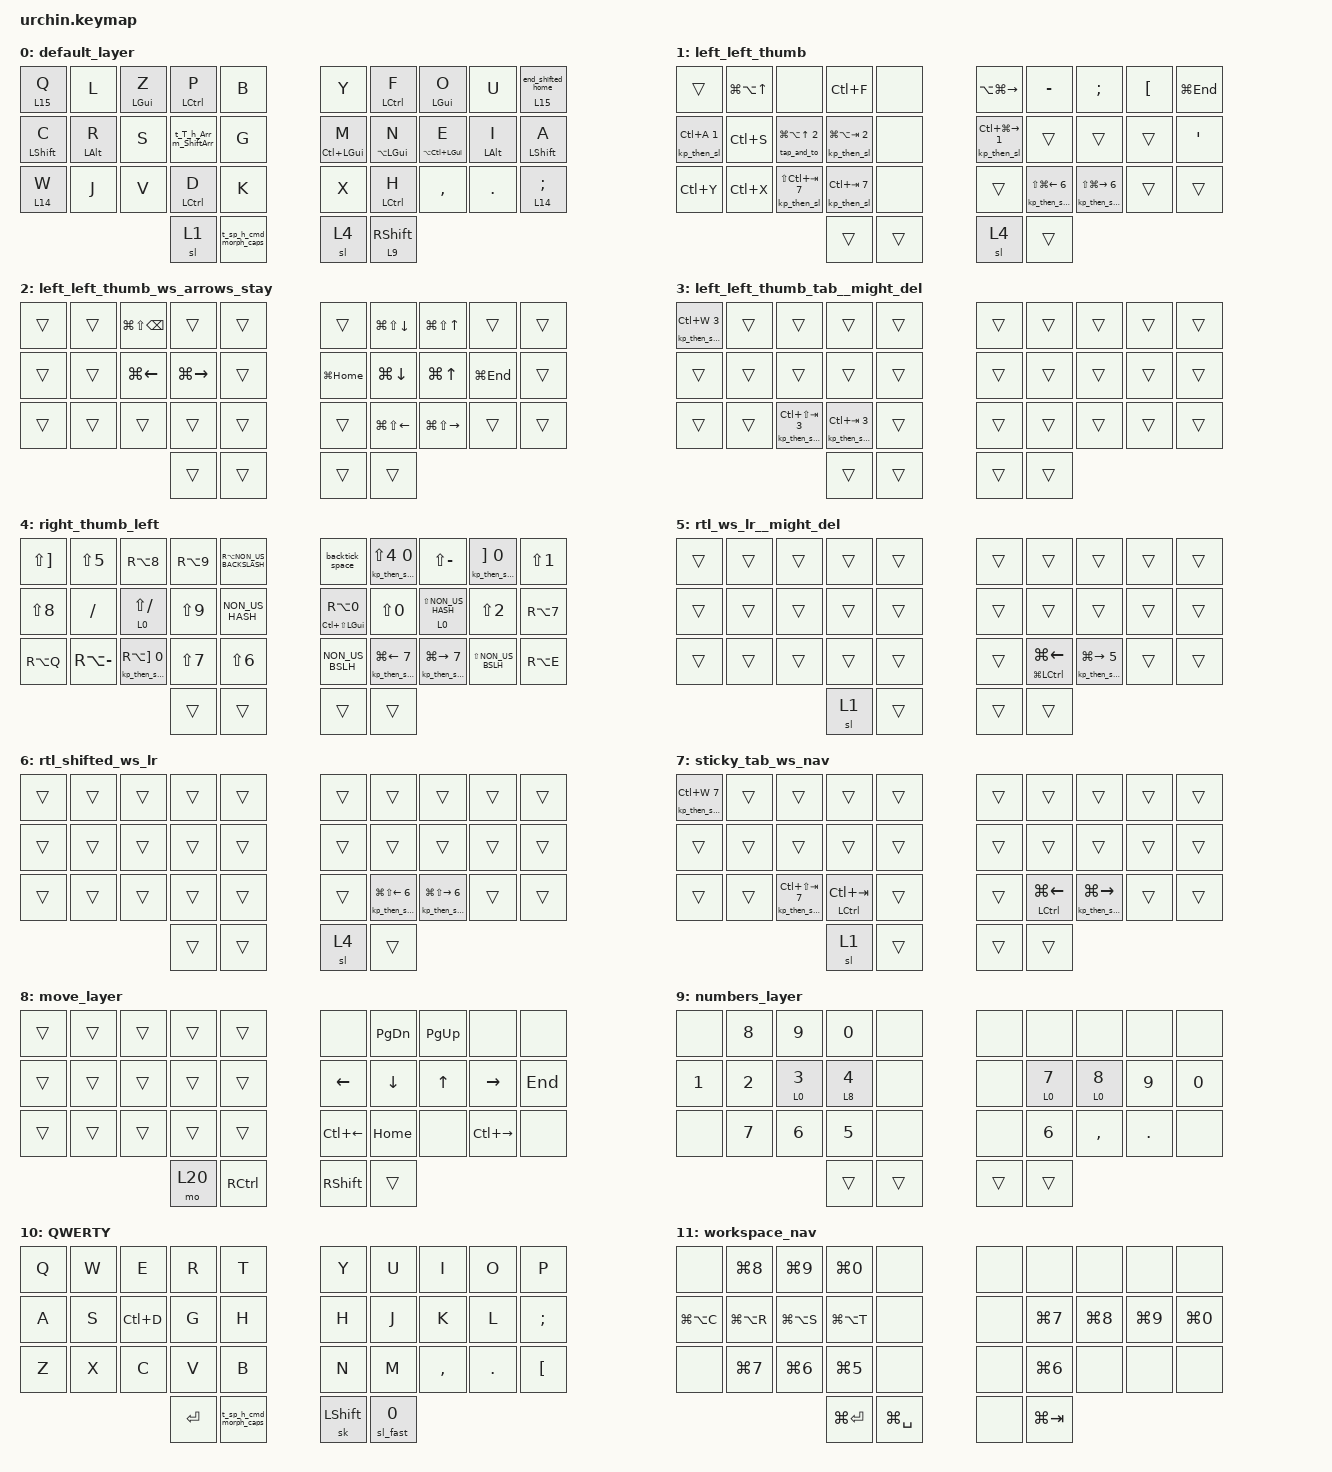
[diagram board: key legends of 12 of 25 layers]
// Copyright (c) 2022 The ZMK Contributors
// SPDX-License-Identifier: MIT

#include <behaviors.dtsi>
#include <dt-bindings/zmk/bt.h>
#include <dt-bindings/zmk/keys.h>
#include <dt-bindings/zmk/pointing.h>

&sk {
    release-after-ms = <1500>;
    quick-release;
};

&lt { flavor = "balanced"; };

&caps_word { continue-list = <UNDERSCORE BACKSPACE DELETE SINGLE_QUOTE DOUBLE_QUOTES SEMICOLON LBRC LEFT_BRACE COLON QUESTION>; };

/ {
    behaviors {
        ht: hold_tap {
            compatible = "zmk,behavior-hold-tap";
            #binding-cells = <2>;
            flavor = "balanced";
            tapping-term-ms = <220>;
            quick-tap-ms = <150>;
            require-prior-idle-ms = <0>;
            bindings = <&kp>, <&kp>;
        };

        htl_undec: htl_undec {
            compatible = "zmk,behavior-hold-tap";
            label = "HTL_UNDEC";
            bindings = <&kp>, <&kp>;

            #binding-cells = <2>;
            tapping-term-ms = <350>;
            hold-trigger-key-positions = <5 6 7 8 9 15 16 17 18 19 25 26 27 28 29 32 33 30 31>;
            flavor = "balanced";
            quick-tap-ms = <175>;
            require-prior-idle-ms = <3>;
            hold-while-undecided;
            hold-trigger-on-release;
        };

        ltl: ltl {
            compatible = "zmk,behavior-hold-tap";
            label = "LTL";
            bindings = <&mo>, <&kp>;

            #binding-cells = <2>;
            tapping-term-ms = <350>;
            quick-tap-ms = <175>;
            require-prior-idle-ms = <3>;
            flavor = "balanced";
            hold-trigger-key-positions = <5 6 7 8 9 15 16 17 18 19 25 26 27 28 29 32 33 30 31>;
        };

        htr_undec: htr_undec {
            compatible = "zmk,behavior-hold-tap";
            label = "HTR_UNDEC";
            bindings = <&kp>, <&kp>;

            #binding-cells = <2>;
            flavor = "balanced";
            tapping-term-ms = <350>;
            hold-trigger-key-positions = <0 1 2 3 4 10 11 12 13 14 20 21 22 23 24 30 31 32 33>;
            require-prior-idle-ms = <3>;
            quick-tap-ms = <175>;
            hold-while-undecided;
            hold-trigger-on-release;
        };

        ltr: ltr {
            compatible = "zmk,behavior-hold-tap";
            label = "LTR";
            bindings = <&mo>, <&kp>;

            #binding-cells = <2>;
            tapping-term-ms = <350>;
            quick-tap-ms = <175>;
            require-prior-idle-ms = <3>;
            flavor = "balanced";
            hold-trigger-key-positions = <0 1 2 3 4 10 11 12 13 14 20 21 22 23 24 30 31 32 33>;
        };

        htr: htr {
            compatible = "zmk,behavior-hold-tap";
            label = "HTR";
            bindings = <&kp>, <&kp>;

            #binding-cells = <2>;
            flavor = "balanced";
            tapping-term-ms = <350>;
            hold-trigger-key-positions = <0 1 2 3 4 10 11 12 13 14 20 21 22 23 24 30 31 32 33>;
            require-prior-idle-ms = <3>;
            quick-tap-ms = <175>;
            hold-trigger-on-release;
            retro-tap;
        };

        htl: htl {
            compatible = "zmk,behavior-hold-tap";
            label = "HTL";
            bindings = <&kp>, <&kp>;

            #binding-cells = <2>;
            tapping-term-ms = <350>;
            hold-trigger-key-positions = <5 6 7 8 9 15 16 17 18 19 25 26 27 28 29 32 33 30 31>;
            flavor = "balanced";
            quick-tap-ms = <175>;
            require-prior-idle-ms = <3>;
            hold-trigger-on-release;
            retro-tap;
        };

        tsk_hmo: tsk_hmo {
            compatible = "zmk,behavior-hold-tap";
            label = "TSK_HMO";
            bindings = <&mo>, <&sk>;

            #binding-cells = <2>;
            tapping-term-ms = <200>;
            flavor = "balanced";
            retro-tap;
            require-prior-idle-ms = <0>;
        };

        slashBackslash: slashBackslash {
            compatible = "zmk,behavior-mod-morph";
            label = "SLASHBACKSLASH";
            bindings = <&kp LS(AMPERSAND)>, <&kp RA(MINUS)>;

            #binding-cells = <0>;
            mods = <(MOD_RSFT)>;
        };

        minusTilde: minusTilde {
            compatible = "zmk,behavior-mod-morph";
            label = "MINUSTILDE";
            bindings = <&kp SLASH>, <&kp RA(RIGHT_BRACKET)>;

            #binding-cells = <0>;
            mods = <(MOD_RSFT)>;
        };

        td_wsnav: td_wsnav {
            compatible = "zmk,behavior-tap-dance";
            label = "TD_WSNAV";
            #binding-cells = <0>;
            bindings = <&lt 17 TAB>, <&mo 11>;
        };

        sticky_number_shift_capsword: sticky_number_shift_capsword {
            compatible = "zmk,behavior-tap-dance";
            label = "STICKY_NUMBER_SHIFT_CAPSWORD";
            #binding-cells = <0>;
            bindings = <&tsk_hmo 9 RSHFT>, <&caps_word>;
        };

        lazy_sl: lazy_sl {
            compatible = "zmk,behavior-sticky-key";
            label = "LAZY_SL";
            bindings = <&mo>;
            #binding-cells = <1>;
            release-after-ms = <1000>;
            lazy;
            quick-release;
            ignore-modifiers;
        };

        htl_undec_idle_req: htl_undec_idle_req {
            compatible = "zmk,behavior-hold-tap";
            label = "HTL_UNDEC_IDLE_REQ";
            bindings = <&kp>, <&kp>;

            #binding-cells = <2>;
            hold-trigger-key-positions = <30 31 32 33 5 6 7 8 9 15 16 17 18 19 25 26 27 28 29>;
            hold-while-undecided;
            flavor = "balanced";
            tapping-term-ms = <350>;
            require-prior-idle-ms = <70>;
        };

        htr_undec_idle_req: htr_undec_idle_req {
            compatible = "zmk,behavior-hold-tap";
            label = "HTR_UNDEC_IDLE_REQ";
            bindings = <&kp>, <&kp>;

            #binding-cells = <2>;
            hold-while-undecided;
            flavor = "balanced";
            tapping-term-ms = <350>;
            require-prior-idle-ms = <70>;
            hold-trigger-key-positions = <0 1 2 3 4 10 11 12 13 14 20 21 22 23 24 30 31 32 33>;
        };

        ltr_idle_required: ltr_idle_required {
            compatible = "zmk,behavior-hold-tap";
            label = "LTR_IDLE_REQUIRED";
            bindings = <&mo>, <&kp>;

            #binding-cells = <2>;
            flavor = "balanced";
            require-prior-idle-ms = <50>;
            hold-trigger-key-positions = <0 1 2 3 4 10 11 12 13 14 20 21 22 23 24 30 31 32 33>;
            tapping-term-ms = <350>;
        };

        htl_idle_req: htl_idle_req {
            compatible = "zmk,behavior-hold-tap";
            label = "HTL_IDLE_REQ";
            bindings = <&kp>, <&kp>;

            #binding-cells = <2>;
            require-prior-idle-ms = <50>;
            tapping-term-ms = <350>;
            hold-trigger-key-positions = <30 31 32 33 5 6 7 8 9 15 16 17 18 19 25 26 27 28 29>;
            flavor = "balanced";
        };

        htr_idle_req: htr_idle_req {
            compatible = "zmk,behavior-hold-tap";
            label = "HTR_IDLE_REQ";
            bindings = <&kp>, <&kp>;

            #binding-cells = <2>;
            require-prior-idle-ms = <50>;
            tapping-term-ms = <350>;
            flavor = "balanced";
            hold-trigger-key-positions = <0 1 2 3 4 10 11 12 13 14 20 21 22 23 24 30 31 33 32>;
        };

        dot_capsword: dot_capsword {
            compatible = "zmk,behavior-mod-morph";
            label = "DOT_CAPSWORD";
            bindings = <&kp DOT>, <&caps_word>;

            #binding-cells = <0>;
            mods = <(MOD_RSFT)>;
        };

        sl_left_tab_morph: sl_left_tab_morph {
            compatible = "zmk,behavior-mod-morph";
            label = "SL_LEFT_TAB_MORPH";
            bindings = <&sl_fast 0>, <&kp TAB>;

            #binding-cells = <0>;
            mods = <(MOD_LCTL|MOD_LSFT|MOD_LGUI|MOD_RCTL|MOD_RSFT|MOD_RGUI)>;
            keep-mods = <(MOD_LCTL|MOD_LSFT|MOD_LGUI|MOD_RCTL|MOD_RSFT|MOD_RGUI)>;
        };

        tap_sl_hold_to: tap_sl_hold_to {
            compatible = "zmk,behavior-hold-tap";
            label = "TAP_SL_HOLD_TO";
            bindings = <&to>, <&sl_fast>;

            #binding-cells = <2>;
            flavor = "balanced";
            tapping-term-ms = <200>;
        };

        t_sp_h_cmd_morph_caps: t_sp_h_cmd_morph_caps {
            compatible = "zmk,behavior-mod-morph";
            label = "T_SP_H_CMD_MORPH_CAPS";
            bindings = <&lt 13 SPACE>, <&t_capsw_h_mo 13 0>;

            #binding-cells = <0>;
            mods = <(MOD_RSFT)>;
            keep-mods = <(MOD_RSFT)>;
        };

        t_capsw_h_mo: t_capsw_h_mo {
            compatible = "zmk,behavior-hold-tap";
            label = "T_CAPSW_H_MO";
            bindings = <&mo>, <&caps_word>;

            #binding-cells = <2>;
            tapping-term-ms = <200>;
            flavor = "balanced";
        };

        h_mo_t_to_r: h_mo_t_to_r {
            compatible = "zmk,behavior-hold-tap";
            label = "H_MO_T_TO_R";
            bindings = <&mo>, <&to>;

            #binding-cells = <2>;
            tapping-term-ms = <250>;
            flavor = "balanced";
            hold-trigger-key-positions = <30 31 32 33 0 1 2 3 4 10 11 12 13 14 20 21 22 23 24>;
        };

        t_T_h_Arr_m_ShiftArr: t_T_h_Arr_m_ShiftArr {
            compatible = "zmk,behavior-mod-morph";
            label = "T_T_H_ARR_M_SHIFTARR";
            bindings = <&ltl 8 T>, <&ltl 0 T>;

            #binding-cells = <0>;
            mods = <(MOD_RSFT)>;
            keep-mods = <(MOD_RSFT)>;
        };

        sl_fast: sl_fast {
            compatible = "zmk,behavior-sticky-key";
            label = "SL_FAST";
            bindings = <&mo>;
            #binding-cells = <1>;
            release-after-ms = <600>;
            quick-release;
        };

        htr_undec_then_sl_fast: htr_undec_then_sl_fast {
            compatible = "zmk,behavior-hold-tap";
            label = "HTR_UNDEC_THEN_SL_FAST";
            bindings = <&kp>, <&kp_then_sl_fast>;

            #binding-cells = <2>;
            flavor = "balanced";
            tapping-term-ms = <350>;
            hold-trigger-key-positions = <0 1 2 3 4 10 11 12 13 14 20 21 22 23 24 30 31 32 33>;
            require-prior-idle-ms = <3>;
            quick-tap-ms = <175>;
            hold-while-undecided;
            hold-trigger-on-release;
        };

        ltl_then_sl: ltl_then_sl {
            compatible = "zmk,behavior-hold-tap";
            label = "LTL_THEN_SL";
            bindings = <&mo>, <&kp_then_sl>;

            #binding-cells = <2>;
            tapping-term-ms = <350>;
            quick-tap-ms = <175>;
            require-prior-idle-ms = <3>;
            flavor = "balanced";
            hold-trigger-key-positions = <5 6 7 8 9 15 16 17 18 19 25 26 27 28 29 32 33 30 31>;
        };

        ltr_then_sl_fast: ltr_then_sl_fast {
            compatible = "zmk,behavior-hold-tap";
            label = "LTR_THEN_SL_FAST";
            bindings = <&mo>, <&kp_then_sl_fast>;

            #binding-cells = <2>;
            tapping-term-ms = <350>;
            quick-tap-ms = <175>;
            require-prior-idle-ms = <3>;
            flavor = "balanced";
            hold-trigger-key-positions = <0 1 2 3 4 10 11 12 13 14 20 21 22 23 24 30 31 32 33>;
        };

        end_shifted_home: end_shifted_home {
            compatible = "zmk,behavior-mod-morph";
            label = "END_SHIFTED_HOME";
            bindings = <&kp END>, <&kp HOME>;

            #binding-cells = <0>;
            mods = <(MOD_LSFT|MOD_RSFT)>;
        };

        ltr_end_shifted_home: ltr_end_shifted_home {
            compatible = "zmk,behavior-hold-tap";
            label = "LTR_END_SHIFTED_HOME";
            bindings = <&mo>, <&end_shifted_home>;

            #binding-cells = <2>;
            tapping-term-ms = <350>;
            quick-tap-ms = <175>;
            require-prior-idle-ms = <3>;
            flavor = "balanced";
            hold-trigger-key-positions = <0 1 2 3 4 10 11 12 13 14 20 21 22 23 24 30 31 32 33>;
        };

        sl_slow: sl_slow {
            compatible = "zmk,behavior-sticky-key";
            label = "SL_SLOW";
            bindings = <&mo>;
            #binding-cells = <1>;
            release-after-ms = <5000>;
            quick-release;
        };

        h_winAlt_t_n_stay_shifted: h_winAlt_t_n_stay_shifted {
            compatible = "zmk,behavior-mod-morph";
            label = "H_WINALT_T_N_STAY_SHIFTED";
            bindings = <&htr LA(LEFT_GUI) N>, <&ltr 22 LG(N)>;

            #binding-cells = <0>;
            mods = <(MOD_LSFT|MOD_RSFT)>;
            keep-mods = <(MOD_LSFT|MOD_RSFT)>;
        };

        h_winCtl_t_m_stay_shifted: h_winCtl_t_m_stay_shifted {
            compatible = "zmk,behavior-mod-morph";
            label = "H_WINCTL_T_M_STAY_SHIFTED";
            bindings = <&htr_undec LC(LEFT_GUI) M>, <&ltr 23 LG(M)>;

            #binding-cells = <0>;
            mods = <(MOD_LSFT|MOD_RSFT)>;
            keep-mods = <(MOD_LSFT|MOD_RSFT)>;
        };

        htr_und_sl_slow_tab_ws_nav: htr_und_sl_slow_tab_ws_nav {
            compatible = "zmk,behavior-hold-tap";
            label = "HTR_UND_SL_SLOW_TAB_WS_NAV";
            bindings = <&kp>, <&kp_then_sl_slow_tab_ws_nav>;

            #binding-cells = <2>;
            flavor = "balanced";
            tapping-term-ms = <350>;
            hold-trigger-key-positions = <0 1 2 3 4 10 11 12 13 14 20 21 22 23 24 30 31 32 33>;
            require-prior-idle-ms = <3>;
            quick-tap-ms = <175>;
            hold-while-undecided;
            hold-trigger-on-release;
        };

        htl_und_sl_slow_tab_ws_nav: htl_und_sl_slow_tab_ws_nav {
            compatible = "zmk,behavior-hold-tap";
            label = "HTL_UND_SL_SLOW_TAB_WS_NAV";
            bindings = <&kp>, <&kp_then_sl_slow_tab_ws_nav>;

            #binding-cells = <2>;
            flavor = "balanced";
            tapping-term-ms = <350>;
            hold-trigger-key-positions = <30 31 32 33 5 6 7 8 9 15 16 17 18 19 25 26 27 28 29 33>;
            require-prior-idle-ms = <3>;
            quick-tap-ms = <175>;
            hold-while-undecided;
            hold-trigger-on-release;
        };
    };

    conditional_layers { compatible = "zmk,conditional-layers"; };

    combos {
        compatible = "zmk,combos";

        to_default {
            bindings = <&to 0>;
            key-positions = <26 27>;
            layers = <7>;
        };

        to_default2 {
            bindings = <&to 0>;
            key-positions = <22 23>;
            layers = <7>;
        };

        to_default3 {
            bindings = <&to 0>;
            key-positions = <12 13>;
            layers = <2>;
        };

        combo_bspc {
            bindings = <&kp BACKSPACE>;
            key-positions = <17 18>;
            timeout-ms = <25>;
        };

        combo_del {
            bindings = <&kp DELETE>;
            key-positions = <16 15>;
            timeout-ms = <30>;
        };

        asdf {
            bindings = <&tog 18>;
            key-positions = <31 30 32 33>;
        };

        combo_enter {
            bindings = <&tap_and_to ENTER 0>;
            key-positions = <22 23>;
            timeout-ms = <25>;
        };

        escape {
            bindings = <&tap_and_to ESCAPE 0>;
            key-positions = <11 12>;
        };

        tab {
            bindings = <&kp TAB>;
            key-positions = <7 8>;
            timeout-ms = <15>;
        };

        combo_enter_right {
            bindings = <&tap_and_to ENTER 0>;
            key-positions = <27 26>;
            timeout-ms = <25>;
        };

        shift_enter {
            bindings = <&tap_and_to LS(ENTER) 0>;
            key-positions = <6 7>;
            timeout-ms = <25>;
        };

        paste {
            bindings = <&kp LC(V)>;
            key-positions = <3 2>;
        };

        shift_paste {
            bindings = <&kp LC(LS(V))>;
            key-positions = <3 4>;
        };

        copy {
            bindings = <&kp_then_sl_slow LC(C) 5>;
            key-positions = <1 2>;
        };

        shift_copy {
            bindings = <&kp_then_sl_slow LC(LS(C)) 5>;
            key-positions = <1 2 3>;
        };

        ctrl_bsp2 {
            bindings = <&kp LC(BACKSPACE)>;
            key-positions = <17 16 18>;
            timeout-ms = <35>;
        };

        select_all {
            bindings = <&kp LC(A)>;
            key-positions = <0 3>;
        };

        normal_keyboard_emulation {
            bindings = <&tog 24>;
            key-positions = <0 4 5 9>;
        };

        select_all_bottom {
            bindings = <&kp LC(A)>;
            key-positions = <20 23>;
        };

        esc2 {
            bindings = <&tap_and_to ESCAPE 0>;
            key-positions = <12 13>;
        };

        bsp2 {
            bindings = <&kp BACKSPACE>;
            key-positions = <17 16>;
            timeout-ms = <25>;
        };
    };

    macros {
        quick_rshift_sk: quick_sk {
            compatible = "zmk,behavior-macro";
            #binding-cells = <0>;
            bindings = <&sk LC(RSHFT)>;
            label = "QUICK_SK";
        };

        kp_then_sl: dollar_sl_right {
            compatible = "zmk,behavior-macro-two-param";
            #binding-cells = <2>;
            bindings = <&macro_param_1to1 &kp MACRO_PLACEHOLDER &macro_param_2to1 &sl MACRO_PLACEHOLDER>;
            label = "DOLLAR_SL_RIGHT";
        };

        tap_and_to: new_macro {
            compatible = "zmk,behavior-macro-two-param";
            #binding-cells = <2>;
            bindings = <&macro_param_1to1 &kp MACRO_PLACEHOLDER &macro_param_2to1 &to MACRO_PLACEHOLDER>;
            label = "NEW_MACRO";
        };

        backtick_space: backtick_space {
            compatible = "zmk,behavior-macro";
            #binding-cells = <0>;
            bindings = <&kp LS(EQUAL) &kp SPACE>;
            label = "BACKTICK_SPACE";
        };

        kp_then_sl_fast: kp_then_sl_fast {
            compatible = "zmk,behavior-macro-two-param";
            #binding-cells = <2>;
            bindings = <&macro_param_1to1 &kp MACRO_PLACEHOLDER &macro_param_2to1 &sl_fast MACRO_PLACEHOLDER>;
            label = "KP_THEN_SL_FAST";
        };

        kp_then_sl_slow: kp_then_sl_slow {
            compatible = "zmk,behavior-macro-two-param";
            #binding-cells = <2>;
            bindings = <&macro_param_1to1 &kp MACRO_PLACEHOLDER &macro_param_2to1 &sl_slow MACRO_PLACEHOLDER>;
            label = "KP_THEN_SL_SLOW";
        };

        kp_then_sl_slow_tab_ws_nav: kp_then_sl_slow__ws_lr {
            compatible = "zmk,behavior-macro-one-param";
            #binding-cells = <1>;
            bindings = <&macro_param_1to1 &kp MACRO_PLACEHOLDER &sl_slow 7>;
            label = "KP_THEN_SL_SLOW__WS_LR";
        };
    };

    keymap {
        compatible = "zmk,keymap";

        default_layer {
            bindings = <
&ltl 15 Q                         &kp L                 &htl_undec LGUI Z  &htl LEFT_CONTROL P        &kp B                   &kp Y            &htr LCTRL F        &htr_undec LGUI O    &kp U                 &ltr_end_shifted_home 15 0
&htl_undec_idle_req LEFT_SHIFT C  &htl_idle_req LALT R  &kp S              &t_T_h_Arr_m_ShiftArr      &kp G                   &htr LC(LGUI) M  &htr LA(LGUI) N     &htr LA(LC(LGUI)) E  &htr_idle_req LALT I  &htr_undec_idle_req LSHIFT A
&ltr 14 W                         &kp J                 &kp V              &htl_undec LEFT_CONTROL D  &kp K                   &kp X            &htr_undec LCTRL H  &kp COMMA            &kp DOT               &ltr 14 SEMICOLON
                                                                           &sl 1                      &t_sp_h_cmd_morph_caps  &sl 4            &tsk_hmo 9 RSHFT
            >;
        };

        left_left_thumb {
            bindings = <
&trans               &kp LG(LA(UP_ARROW))  &none                           &kp LC(F)                  &none   &kp LA(LG(RIGHT))            &kp MINUS                        &kp SEMICOLON                     &kp LEFT_BRACKET  &kp LG(END)
&kp_then_sl LC(A) 1  &kp LC(S)             &tap_and_to LG(LA(UP_ARROW)) 2  &kp_then_sl LG(LA(TAB)) 2  &none   &kp_then_sl LC(LG(RIGHT)) 1  &trans                           &trans                            &trans            &kp SQT
&kp LC(Y)            &kp LC(X)             &kp_then_sl LS(LC(TAB)) 7       &kp_then_sl LC(TAB) 7      &none   &trans                       &kp_then_sl_slow LS(LG(LEFT)) 6  &kp_then_sl_slow LS(LG(RIGHT)) 6  &trans            &trans
                                                                           &trans                     &trans  &sl 4                        &trans
            >;
        };

        left_left_thumb_ws_arrows_stay {
            bindings = <
&trans  &trans  &kp LG(LS(BACKSPACE))  &trans         &trans  &trans        &kp LG(LS(DOWN))  &kp LG(LS(UP_ARROW))  &trans       &trans
&trans  &trans  &kp LG(LEFT)           &kp LG(RIGHT)  &trans  &kp LG(HOME)  &kp LG(DOWN)      &kp LG(UP)            &kp LG(END)  &trans
&trans  &trans  &trans                 &trans         &trans  &trans        &kp LG(LS(LEFT))  &kp LG(LS(RIGHT))     &trans       &trans
                                       &trans         &trans  &trans        &trans
            >;
        };

        left_left_thumb_tab__might_del {
            bindings = <
&kp_then_sl_slow LC(W) 3  &trans  &trans                          &trans                      &trans  &trans  &trans  &trans  &trans  &trans
&trans                    &trans  &trans                          &trans                      &trans  &trans  &trans  &trans  &trans  &trans
&trans                    &trans  &kp_then_sl_slow LC(LS(TAB)) 3  &kp_then_sl_slow LC(TAB) 3  &trans  &trans  &trans  &trans  &trans  &trans
                                                                  &trans                      &trans  &trans  &trans
            >;
        };

        right_thumb_left {
            bindings = <
&kp LS(RIGHT_BRACKET)  &kp LS(NUMBER_5)  &kp RA(N8)                            &kp RA(N9)  &kp RA(NON_US_BACKSLASH)  &backtick_space                 &kp_then_sl_fast LS(NUMBER_4) 0  &kp LS(MINUS)                 &kp_then_sl_fast RIGHT_BRACKET 0  &kp LS(NUMBER_1)
&kp LS(N8)             &kp SLASH         &lt 0 LS(SLASH)                       &kp LS(N9)  &kp NON_US_HASH           &htr_undec LC(LS(LGUI)) RA(N0)  &kp LS(N0)                       &lt 0 LS(NON_US_HASH)         &kp LS(NUMBER_2)                  &kp RA(N7)
&kp RA(Q)              &kp RA(MINUS)     &kp_then_sl_fast RA(RIGHT_BRACKET) 0  &kp LS(N7)  &kp LS(NUMBER_6)          &kp NON_US_BSLH                 &kp_then_sl_slow LG(LEFT) 7      &kp_then_sl_slow LG(RIGHT) 7  &kp LS(NON_US_BSLH)               &kp RA(E)
                                                                               &trans      &trans                    &trans                          &trans
            >;
        };

        rtl_ws_lr__might_del {
            bindings = <
&trans  &trans  &trans  &trans  &trans  &trans  &trans                                                 &trans                        &trans  &trans
&trans  &trans  &trans  &trans  &trans  &trans  &trans                                                 &trans                        &trans  &trans
&trans  &trans  &trans  &trans  &trans  &trans  &htl_und_sl_slow_tab_ws_nav LG(LEFT_CONTROL) LG(LEFT)  &kp_then_sl_slow LG(RIGHT) 5  &trans  &trans
                        &sl 1   &trans  &trans  &trans
            >;
        };

        rtl_shifted_ws_lr {
            bindings = <
&trans  &trans  &trans  &trans  &trans  &trans  &trans                           &trans                            &trans  &trans
&trans  &trans  &trans  &trans  &trans  &trans  &trans                           &trans                            &trans  &trans
&trans  &trans  &trans  &trans  &trans  &trans  &kp_then_sl_slow LG(LS(LEFT)) 6  &kp_then_sl_slow LG(LS(RIGHT)) 6  &trans  &trans
                        &trans  &trans  &sl 4   &trans
            >;
        };

        sticky_tab_ws_nav {
            bindings = <
&kp_then_sl_slow LC(W) 7  &trans  &trans                          &trans                                            &trans  &trans  &trans                                             &trans                                 &trans  &trans
&trans                    &trans  &trans                          &trans                                            &trans  &trans  &trans                                             &trans                                 &trans  &trans
&trans                    &trans  &kp_then_sl_slow LC(LS(TAB)) 7  &htl_und_sl_slow_tab_ws_nav LEFT_CONTROL LC(TAB)  &trans  &trans  &htr_und_sl_slow_tab_ws_nav LEFT_CONTROL LG(LEFT)  &kp_then_sl_slow_tab_ws_nav LG(RIGHT)  &trans  &trans
                                                                  &sl 1                                             &trans  &trans  &trans
            >;
        };

        move_layer {
            bindings = <
&trans  &trans  &trans  &trans  &trans             &none         &kp PAGE_DOWN  &kp PG_UP     &none          &none
&trans  &trans  &trans  &trans  &trans             &kp LEFT      &kp DOWN       &kp UP_ARROW  &kp RIGHT      &kp END
&trans  &trans  &trans  &trans  &trans             &kp LC(LEFT)  &kp HOME       &none         &kp LC(RIGHT)  &none
                        &mo 20  &kp RIGHT_CONTROL  &kp RSHIFT    &trans
            >;
        };

        numbers_layer {
            bindings = <
&none   &kp N8  &kp N9           &kp N0           &none   &none   &none      &none      &none    &none
&kp N1  &kp N2  &ltl 0 NUMBER_3  &ltl 8 NUMBER_4  &none   &none   &ltr 0 N7  &ltr 0 N8  &kp N9   &kp N0
&none   &kp N7  &kp N6           &kp N5           &none   &none   &kp N6     &kp COMMA  &kp DOT  &none
                                 &trans           &trans  &trans  &trans
            >;
        };

        QWERTY {
            bindings = <
&kp Q  &kp W  &kp E      &kp R      &kp T                   &kp Y      &kp U       &kp I      &kp O    &kp P
&kp A  &kp S  &kp LC(D)  &kp G      &kp H                   &kp H      &kp J       &kp K      &kp L    &kp SEMI
&kp Z  &kp X  &kp C      &kp V      &kp B                   &kp N      &kp M       &kp COMMA  &kp DOT  &kp LBKT
                         &kp ENTER  &t_sp_h_cmd_morph_caps  &sk LSHFT  &sl_fast 0
            >;
        };

        workspace_nav {
            bindings = <
&none          &kp LG(N8)     &kp LG(N9)     &kp LG(N0)     &none          &none  &none             &none       &none       &none
&kp LG(LA(C))  &kp LG(LA(R))  &kp LG(LA(S))  &kp LG(LA(T))  &none          &none  &kp LG(N7)        &kp LG(N8)  &kp LG(N9)  &kp LG(N0)
&none          &kp LG(N7)     &kp LG(N6)     &kp LG(N5)     &none          &none  &kp LG(NUMBER_6)  &none       &none       &none
                                             &kp LG(ENTER)  &kp LG(SPACE)  &none  &kp LG(TAB)
            >;
        };

        adv_ws_nav {
            bindings = <
&none           &kp LG(LC(N8))  &kp LG(LC(N9))  &kp LG(LC(N0))     &none              &none  &none             &none       &none       &none
&kp LG(LC(N1))  &kp LG(LC(N2))  &kp LG(LC(N3))  &kp LG(LC(N4))     &none              &none  &kp LG(N7)        &kp LG(N8)  &kp LG(N9)  &kp LG(N0)
&none           &kp LG(LC(N7))  &kp LG(LC(N6))  &kp LG(LC(N5))     &none              &none  &kp LG(NUMBER_6)  &none       &none       &none
                                                &kp LG(LC(ENTER))  &kp LG(LC(SPACE))  &none  &kp LG(TAB)
            >;
        };

        commands_and_mouse {
            bindings = <
&none      &none      &kp LS(LG(BACKSPACE))  &none      &none          &none      &none          &msc SCRL_UP    &none  &none
&kp LC(A)  &kp LC(S)  &kp LC(D)              &kp LC(F)  &kp BACKSPACE  &none      &kp LC(SLASH)  &msc SCRL_DOWN  &none  &kp LC(RIGHT_BRACKET)
&kp LC(Y)  &kp LC(X)  &kp LC(C)              &kp LC(V)  &kp DEL        &none      &none          &none           &none  &none
                                             &none      &none          &kp LSHFT  &none
            >;
        };

        Function {
            bindings = <
&none   &none   &kp F11  &none   &none  &none  &none   &kp F12  &none   &none
&kp F1  &kp F2  &kp F3   &kp F4  &none  &none  &kp F7  &kp F8   &kp F9  &kp F10
&none   &none   &none    &kp F5  &none  &none  &kp F6  &none    &none   &none
                         &none   &none  &none  &none
            >;
        };

        bt_reset_trans_left {
            bindings = <
&none   &none  &none  &none       &bt BT_SEL 0  &none  &none  &sys_reset  &none  &none
&mo 17  &none  &none  &none       &bt BT_SEL 1  &none  &none  &none       &none  &mo 17
&none   &none  &none  &bt BT_CLR  &bt BT_SEL 2  &none  &none  &none       &none  &none
                      &none       &none         &none  &none
            >;
        };

        bt_reset_trans_right {
            bindings = <
&none   &none  &none  &none  &none  &none  &none  &none  &none  &none
&mo 17  &none  &none  &none  &none  &none  &none  &none  &none  &mo 17
&none   &none  &none  &none  &none  &none  &none  &none  &none  &none
                      &none  &none  &none  &none
            >;
        };

        bluetooth_and_reset {
            bindings = <
&none  &bootloader  &none  &none           &bt BT_SEL 0  &none  &none  &none  &bootloader  &none
&none  &sys_reset   &none  &studio_unlock  &bt BT_SEL 1  &none  &none  &none  &sys_reset   &none
&none  &none        &none  &bt BT_CLR      &bt BT_SEL 2  &none  &none  &none  &none        &none
                           &none           &none         &none  &none
            >;
        };

        qwerty_with_mods {
            bindings = <
&ltl 15 Q                         &kp W                 &htl LGUI E  &htl LEFT_CONTROL R        &kp T                   &kp Y             &htr LCTRL U             &htr LGUI I  &kp O                 &ltr 16 TAB
&htl_undec_idle_req LEFT_SHIFT A  &htl_idle_req LALT S  &ltl 0 D     &ltl 8 F                   &kp G                   &kp H             &ltr_idle_required 11 J  &ltr 0 K     &htr_idle_req LALT L  &htr_undec_idle_req LSHIFT P
&ltr 14 Z                         &kp X                 &kp C        &htl_undec LEFT_CONTROL V  &kp B                   &kp N             &htr_undec LCTRL M       &kp COMMA    &kp DOT               &h_mo_t_to_r 14 19
                                                                     &lt 0 ENTER                &t_sp_h_cmd_morph_caps  &tsk_hmo 9 RSHFT  &sl_fast 0
            >;
        };

        resize_split {
            bindings = <
&trans  &trans  &trans  &trans  &trans  &trans  &trans             &kp LS(LA(LC(U)))  &trans             &trans
&trans  &trans  &trans  &trans  &trans  &trans  &kp LS(LA(LC(L)))  &kp LA(LS(LC(D)))  &kp LA(LS(LC(R)))  &trans
&trans  &trans  &trans  &trans  &trans  &trans  &trans             &trans             &trans             &trans
                        &trans  &trans  &trans  &trans
            >;
        };

        gaming {
            bindings = <
&kp TAB           &kp Q  &kp R  &kp E           &kp T      &kp Y   &kp U   &kp I      &kp O    &kp P
&kp LEFT_SHIFT    &kp A  &kp W  &kp D           &kp G      &kp H   &kp J   &kp K      &kp L    &kp SEMI
&kp LEFT_CONTROL  &kp X  &kp S  &kp LEFT_SHIFT  &kp B      &kp N   &kp M   &kp COMMA  &kp DOT  &kp FSLH
                                &trans          &kp SPACE  &trans  &trans
            >;
        };

        ws_move {
            bindings = <
&trans  &trans  &trans  &trans  &trans  &trans  &kp_then_sl_fast LG(RA(RIGHT)) 0  &kp LG(UP_ARROW)  &trans             &trans
&trans  &trans  &trans  &trans  &trans  &trans  &ltr 11 LG(LEFT)                  &kp LG(RIGHT)     &kp LC(LG(RIGHT))  &trans
&trans  &trans  &trans  &trans  &trans  &trans  &htr LCTRL LG(DOWN)               &trans            &trans             &trans
                        &trans  &trans  &trans  &trans
            >;
        };

        shifted_win_alt_left {
            bindings = <
&kp LG(LA(LS(W)))  &kp LS(LG(LA(L)))  &kp LS(LA(LG(Z)))  &kp LS(LG(LA(P)))  &kp LG(LA(LS(B)))  &trans  &trans  &trans  &trans  &trans
&kp LS(LA(LG(C)))  &kp LS(LG(LA(R)))  &kp LS(LG(LA(S)))  &kp LS(LG(LA(T)))  &kp LS(LA(LG(H)))  &trans  &trans  &trans  &trans  &trans
&kp LS(LA(LG(Q)))  &kp LS(LG(LA(J)))  &kp LS(LA(LG(V)))  &kp LS(LA(LG(D)))  &kp LS(LA(LG(K)))  &trans  &trans  &trans  &trans  &trans
                                                         &trans             &trans             &trans  &trans
            >;
        };

        shifted_win_ctrl_left {
            bindings = <
&kp LG(LS(LC(W)))  &kp LS(LG(LC(L)))  &kp LS(LG(LC(Z)))  &kp LS(LG(LC(P)))  &kp LG(LS(LC(B)))  &trans  &trans  &trans  &trans  &trans
&kp LS(LG(LC(C)))  &kp LS(LG(LC(R)))  &kp LS(LG(LC(S)))  &kp LS(LG(LC(T)))  &kp LS(LG(LC(H)))  &trans  &trans  &trans  &trans  &trans
&kp LS(LG(LC(Q)))  &kp LS(LG(LC(J)))  &kp LS(LG(LC(V)))  &kp LS(LG(LC(D)))  &kp LS(LG(LC(K)))  &trans  &trans  &trans  &trans  &trans
                                                         &trans             &trans             &trans  &trans
            >;
        };

        qwerty_no_mods_but_thumbs {
            bindings = <
&kp N1    &kp N2  &kp N3  &kp E     &kp R      &kp I      &kp O      &kp N0    &kp MINUS  &kp EQUAL
&kp TAB   &kp Q   &kp W   &kp D     &kp F      &kp K      &kp L      &kp P     &kp LBKT   &kp RBKT
&kp CAPS  &kp A   &kp S   &kp X     &kp C      &kp COMMA  &kp DOT    &kp SEMI  &kp APOS   &kp NON_US_HASH
                          &kp LALT  &kp SPACE  &kp RALT   &kp RCTRL
            >;
        };
    };
};
